AUTOSAR XML (schema 4-0-3)
standard types defined: UInt32, UInt8
package /AUTOSAR_Platform/DataConstrs
  range DC_UInt8: raw 0..255
package /PATAC/MSM/ComponentTypes
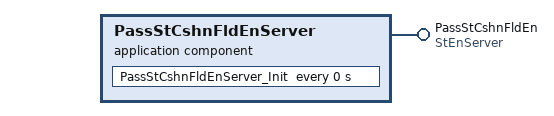
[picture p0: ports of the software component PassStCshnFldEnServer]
  application sw component type PassStCshnFldEnServer
    provide port PassStCshnFldEn: provided-com-specs=[{operation=Clear, queue-length=1}, {operation=Get, queue-length=1}, {operation=Set, queue-length=1}], provided-interface=StEnServer
    behavior PassStCshnFldEnServer_InternalBehavior
      operation invoked event OIT_PassStCshnFldEn_Clear_PassStCshnFldEn_Clear: start-on-event=PassStCshnFldEn_Clear, operation=PassStCshnFldEn.Clear
      operation invoked event OIT_PassStCshnFldEn_Get_PassStCshnFldEn_Get: start-on-event=PassStCshnFldEn_Get, operation=PassStCshnFldEn.Get
      operation invoked event OIT_PassStCshnFldEn_Set_PassStCshnFldEn_Set: start-on-event=PassStCshnFldEn_Set, operation=PassStCshnFldEn.Set
      timing event PassStCshnFldEnServer_InitEvent: start-on-event=PassStCshnFldEnServer_Init, period=0
      4 x runnable:
        PassStCshnFldEn_Clear
        PassStCshnFldEn_Get
        PassStCshnFldEn_Set
        PassStCshnFldEnServer_Init
  swc implementation PassStCshnFldEnServer_Implementation: behavior=PassStCshnFldEnServer_InternalBehavior
    code-descriptors:
      code Default: artifact-descriptors=autosar-engineering-object={short-label=Default, category=SWSRC}
package /PATAC/MSM/ModeAdjust/PortInterface
  client server interface StEnServer
    operation Clear
      arg data: type=UInt8, direction=IN, server-argument-impl-policy=USE-ARGUMENT-TYPE
    operation Get
      arg data: type=UInt32, direction=OUT, server-argument-impl-policy=USE-ARGUMENT-TYPE
    operation Set
      arg data: type=UInt8, direction=IN, server-argument-impl-policy=USE-ARGUMENT-TYPE
